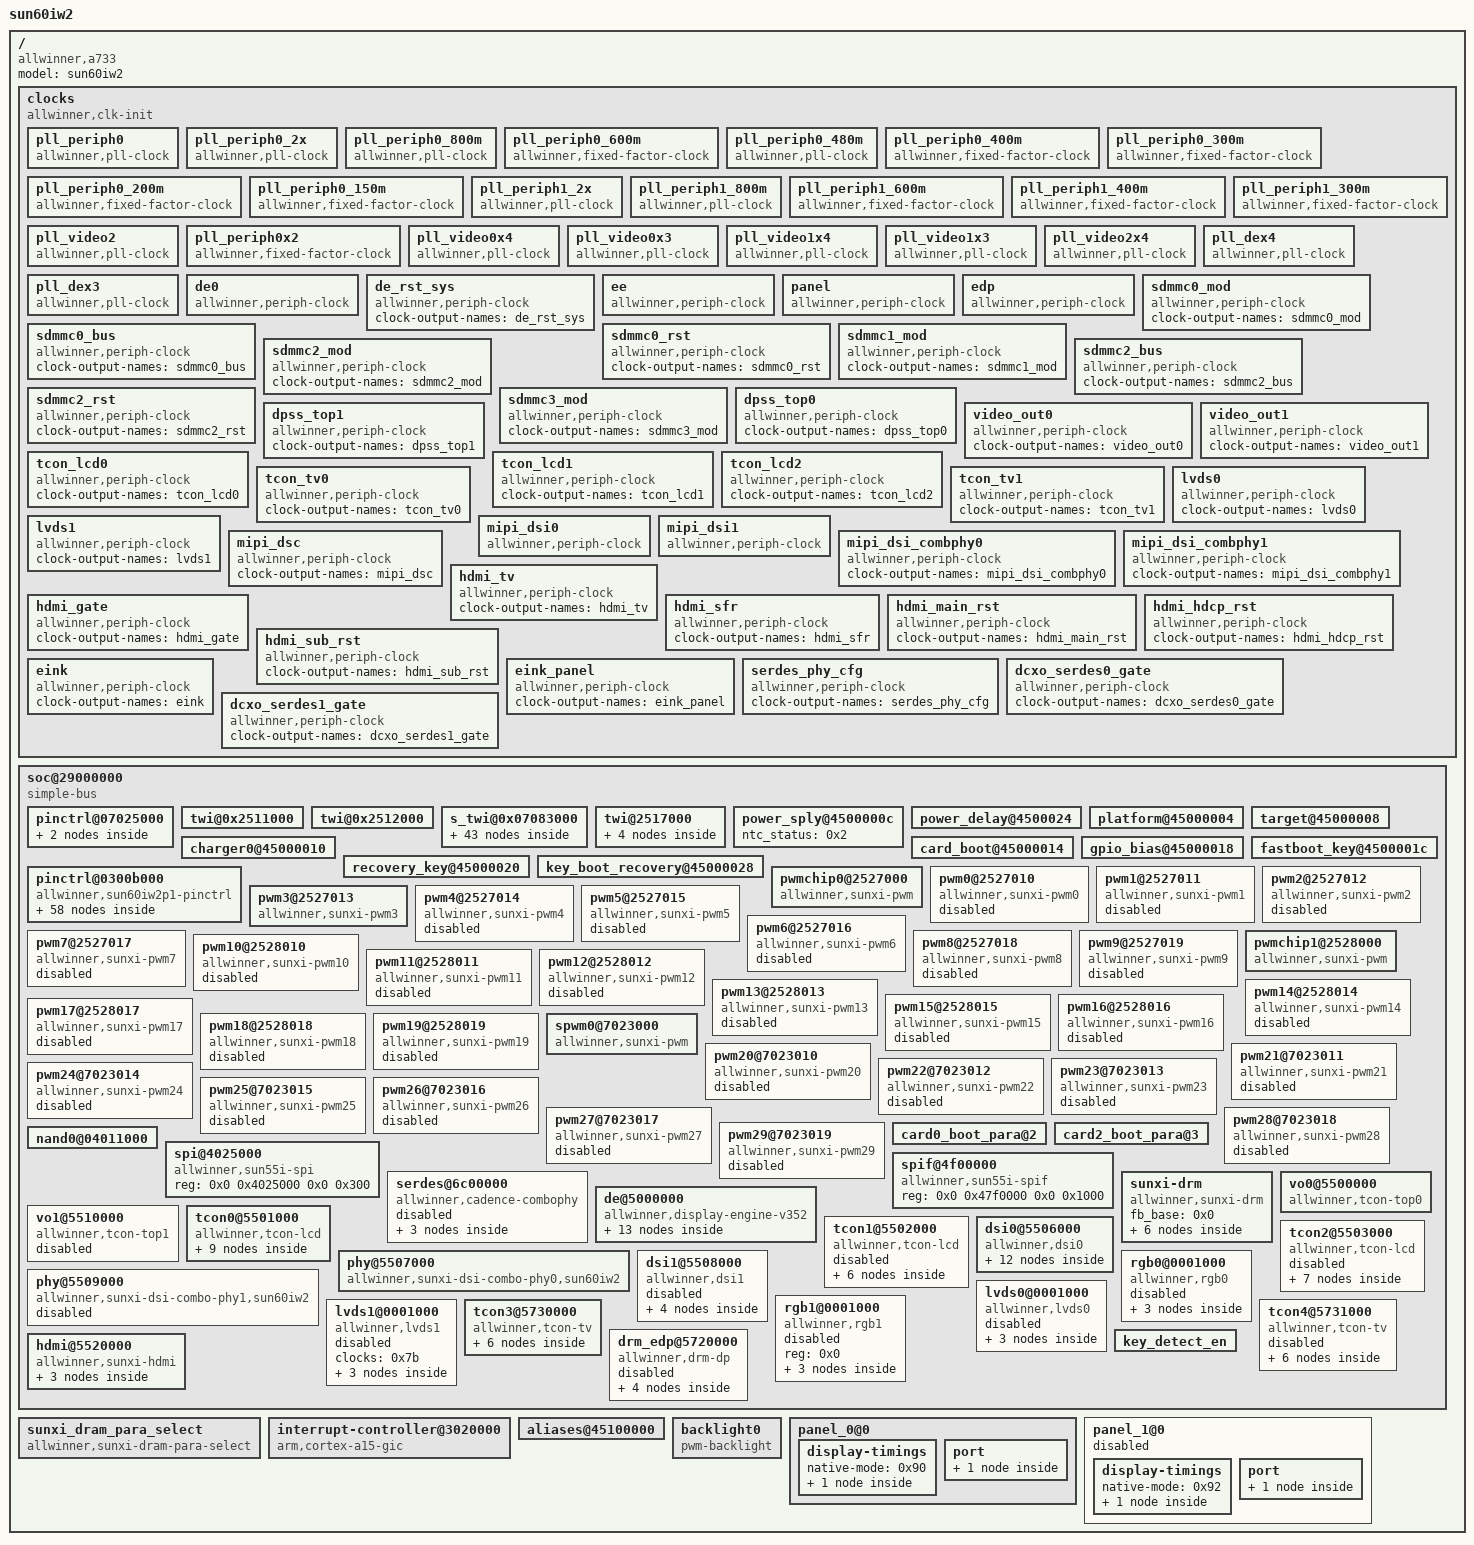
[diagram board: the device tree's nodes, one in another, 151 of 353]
/dts-v1/;

/ {
	model = "sun60iw2";
	compatible = "allwinner,a733", "arm,sun60iw2p1";
	#address-cells = <0x2>;
	#size-cells = <0x2>;

	clocks {
		compatible = "allwinner,clk-init";
		device_type = "clocks";
		#address-cells = <0x2>;
		#size-cells = <0x2>;
		ranges;
		reg = <0x0 0x2002000 0x0 0x2000 0x0 0x7010000 0x0 0x400>;

		pll_periph0 {
			#clock-cells = <0x0>;
			compatible = "allwinner,pll-clock";
			assigned-clock-rates = <0x23c34600>;
			lock-mode = "new";
			clock-output-names = "pll_periph0";
			phandle = <0x7>;
		};

		pll_periph0_2x {
			#clock-cells = <0x0>;
			compatible = "allwinner,pll-clock";
			lock-mode = "new";
			clock-output-names = "pll_periph0_2x";
			phandle = <0x1>;
		};

		pll_periph0_800m {
			#clock-cells = <0x0>;
			compatible = "allwinner,pll-clock";
			lock-mode = "new";
			clock-output-names = "pll_periph0_800m";
		};

		pll_periph0_600m {
			#clock-cells = <0x0>;
			compatible = "allwinner,fixed-factor-clock";
			clocks = <0x1>;
			clock-mult = <0x1>;
			clock-div = <0x2>;
			clock-output-names = "pll_periph0_600m";
			phandle = <0x2>;
		};

		pll_periph0_480m {
			#clock-cells = <0x0>;
			compatible = "allwinner,pll-clock";
			lock-mode = "new";
			clock-output-names = "pll_periph0_480m";
		};

		pll_periph0_400m {
			#clock-cells = <0x0>;
			compatible = "allwinner,fixed-factor-clock";
			clocks = <0x1>;
			clock-mult = <0x1>;
			clock-div = <0x3>;
			clock-output-names = "pll_periph0_400m";
			phandle = <0x3>;
		};

		pll_periph0_300m {
			#clock-cells = <0x0>;
			compatible = "allwinner,fixed-factor-clock";
			clocks = <0x2>;
			clock-mult = <0x1>;
			clock-div = <0x2>;
			clock-output-names = "pll_periph0_300m";
			phandle = <0x4>;
		};

		pll_periph0_200m {
			#clock-cells = <0x0>;
			compatible = "allwinner,fixed-factor-clock";
			clocks = <0x3>;
			clock-mult = <0x1>;
			clock-div = <0x2>;
			clock-output-names = "pll_periph0_200m";
		};

		pll_periph0_150m {
			#clock-cells = <0x0>;
			compatible = "allwinner,fixed-factor-clock";
			clocks = <0x4>;
			clock-mult = <0x1>;
			clock-div = <0x2>;
			clock-output-names = "pll_periph0_150m";
			phandle = <0x10>;
		};

		pll_periph1_2x {
			#clock-cells = <0x0>;
			compatible = "allwinner,pll-clock";
			lock-mode = "new";
			clock-output-names = "pll_periph1_2x";
			phandle = <0x5>;
		};

		pll_periph1_800m {
			#clock-cells = <0x0>;
			compatible = "allwinner,pll-clock";
			lock-mode = "new";
			clock-output-names = "pll_periph1_800m";
		};

		pll_periph1_600m {
			#clock-cells = <0x0>;
			compatible = "allwinner,fixed-factor-clock";
			clocks = <0x5>;
			clock-mult = <0x1>;
			clock-div = <0x2>;
			clock-output-names = "pll_periph1_600m";
			phandle = <0x6>;
		};

		pll_periph1_400m {
			#clock-cells = <0x0>;
			compatible = "allwinner,fixed-factor-clock";
			clocks = <0x5>;
			clock-mult = <0x1>;
			clock-div = <0x3>;
			clock-output-names = "pll_periph1_400m";
		};

		pll_periph1_300m {
			#clock-cells = <0x0>;
			compatible = "allwinner,fixed-factor-clock";
			clocks = <0x6>;
			clock-mult = <0x1>;
			clock-div = <0x2>;
			clock-output-names = "pll_periph1_300m";
		};

		pll_video2 {
			#clock-cells = <0x0>;
			compatible = "allwinner,pll-clock";
			lock-mode = "new";
			clock-output-names = "pll_video2";
			phandle = <0xc>;
		};

		pll_periph0x2 {
			#clock-cells = <0x0>;
			compatible = "allwinner,fixed-factor-clock";
			clocks = <0x7>;
			clock-mult = <0x2>;
			clock-div = <0x1>;
			clock-output-names = "pll_periph0x2";
			phandle = <0xa>;
		};

		pll_video0x4 {
			#clock-cells = <0x0>;
			compatible = "allwinner,pll-clock";
			lock-mode = "new";
			clock-output-names = "pll_video0x4";
		};

		pll_video0x3 {
			#clock-cells = <0x0>;
			compatible = "allwinner,pll-clock";
			lock-mode = "new";
			clock-output-names = "pll_video0x3";
		};

		pll_video1x4 {
			#clock-cells = <0x0>;
			compatible = "allwinner,pll-clock";
			lock-mode = "new";
			clock-output-names = "pll_video1x4";
			phandle = <0xf>;
		};

		pll_video1x3 {
			#clock-cells = <0x0>;
			compatible = "allwinner,pll-clock";
			lock-mode = "new";
			clock-output-names = "pll_video1x3";
		};

		pll_video2x4 {
			#clock-cells = <0x0>;
			compatible = "allwinner,pll-clock";
			lock-mode = "new";
			clock-output-names = "pll_video2x4";
		};

		pll_dex4 {
			#clock-cells = <0x0>;
			compatible = "allwinner,pll-clock";
			lock-mode = "new";
			clock-output-names = "pll_dex4";
		};

		pll_dex3 {
			#clock-cells = <0x0>;
			compatible = "allwinner,pll-clock";
			lock-mode = "new";
			clock-output-names = "pll_dex3";
			phandle = <0x8>;
		};

		de0 {
			#clock-cells = <0x0>;
			compatible = "allwinner,periph-clock";
			clock-output-names = "de0";
			assigned-clock-parents = <0x8>;
			assigned-clock-rates = <0x297c1e00>;
			assigned-clocks = <0x9>;
			phandle = <0x9>;
		};

		de_rst_sys {
			#clock-cells = <0x0>;
			compatible = "allwinner,periph-clock";
			clock-output-names = "de_rst_sys";
		};

		ee {
			#clock-cells = <0x0>;
			compatible = "allwinner,periph-clock";
			assigned-clock-parents = <0xa>;
			assigned-clock-rates = <0x11e1a300>;
			assigned-clocks = <0xb>;
			clock-output-names = "ee";
			phandle = <0xb>;
		};

		panel {
			#clock-cells = <0x0>;
			compatible = "allwinner,periph-clock";
			assigned-clock-parents = <0xc>;
			assigned-clock-rates = <0x1c9c380>;
			assigned-clocks = <0xd>;
			clock-output-names = "panel";
			phandle = <0xd>;
		};

		edp {
			#clock-cells = <0x0>;
			compatible = "allwinner,periph-clock";
			assigned-clocks = <0xe>;
			assigned-clock-parents = <0xf>;
			clock-output-names = "edp";
			phandle = <0xe>;
		};

		sdmmc0_mod {
			#clock-cells = <0x0>;
			compatible = "allwinner,periph-clock";
			clock-output-names = "sdmmc0_mod";
		};

		sdmmc0_bus {
			#clock-cells = <0x0>;
			compatible = "allwinner,periph-clock";
			clock-output-names = "sdmmc0_bus";
		};

		sdmmc0_rst {
			#clock-cells = <0x0>;
			compatible = "allwinner,periph-clock";
			clock-output-names = "sdmmc0_rst";
		};

		sdmmc1_mod {
			#clock-cells = <0x0>;
			compatible = "allwinner,periph-clock";
			clock-output-names = "sdmmc1_mod";
		};

		sdmmc2_mod {
			#clock-cells = <0x0>;
			compatible = "allwinner,periph-clock";
			clock-output-names = "sdmmc2_mod";
		};

		sdmmc2_bus {
			#clock-cells = <0x0>;
			compatible = "allwinner,periph-clock";
			clock-output-names = "sdmmc2_bus";
		};

		sdmmc2_rst {
			#clock-cells = <0x0>;
			compatible = "allwinner,periph-clock";
			clock-output-names = "sdmmc2_rst";
		};

		sdmmc3_mod {
			#clock-cells = <0x0>;
			compatible = "allwinner,periph-clock";
			clock-output-names = "sdmmc3_mod";
		};

		dpss_top0 {
			#clock-cells = <0x0>;
			compatible = "allwinner,periph-clock";
			clock-output-names = "dpss_top0";
			phandle = <0x5a>;
		};

		dpss_top1 {
			#clock-cells = <0x0>;
			compatible = "allwinner,periph-clock";
			clock-output-names = "dpss_top1";
			phandle = <0x5b>;
		};

		video_out0 {
			#clock-cells = <0x0>;
			compatible = "allwinner,periph-clock";
			clock-output-names = "video_out0";
		};

		video_out1 {
			#clock-cells = <0x0>;
			compatible = "allwinner,periph-clock";
			clock-output-names = "video_out1";
		};

		tcon_lcd0 {
			#clock-cells = <0x0>;
			compatible = "allwinner,periph-clock";
			clock-output-names = "tcon_lcd0";
			phandle = <0x5c>;
		};

		tcon_lcd1 {
			#clock-cells = <0x0>;
			compatible = "allwinner,periph-clock";
			clock-output-names = "tcon_lcd1";
			phandle = <0x63>;
		};

		tcon_lcd2 {
			#clock-cells = <0x0>;
			compatible = "allwinner,periph-clock";
			clock-output-names = "tcon_lcd2";
			phandle = <0x67>;
		};

		tcon_tv0 {
			#clock-cells = <0x0>;
			compatible = "allwinner,periph-clock";
			clock-output-names = "tcon_tv0";
			phandle = <0x7e>;
		};

		tcon_tv1 {
			#clock-cells = <0x0>;
			compatible = "allwinner,periph-clock";
			clock-output-names = "tcon_tv1";
			phandle = <0x82>;
		};

		lvds0 {
			#clock-cells = <0x0>;
			compatible = "allwinner,periph-clock";
			clock-output-names = "lvds0";
			phandle = <0x79>;
		};

		lvds1 {
			#clock-cells = <0x0>;
			compatible = "allwinner,periph-clock";
			clock-output-names = "lvds1";
			phandle = <0x7b>;
		};

		mipi_dsi0 {
			#clock-cells = <0x0>;
			compatible = "allwinner,periph-clock";
			assigned-clock-parents = <0x10>;
			assigned-clock-rates = <0x8f0d180>;
			clock-output-names = "mipi_dsi0";
			phandle = <0x6c>;
		};

		mipi_dsi1 {
			#clock-cells = <0x0>;
			compatible = "allwinner,periph-clock";
			assigned-clock-parents = <0x10>;
			assigned-clock-rates = <0x8f0d180>;
			clock-output-names = "mipi_dsi1";
			phandle = <0x75>;
		};

		mipi_dsc {
			#clock-cells = <0x0>;
			compatible = "allwinner,periph-clock";
			clock-output-names = "mipi_dsc";
			phandle = <0x6d>;
		};

		mipi_dsi_combphy0 {
			#clock-cells = <0x0>;
			compatible = "allwinner,periph-clock";
			clock-output-names = "mipi_dsi_combphy0";
		};

		mipi_dsi_combphy1 {
			#clock-cells = <0x0>;
			compatible = "allwinner,periph-clock";
			clock-output-names = "mipi_dsi_combphy1";
		};

		hdmi_tv {
			#clock-cells = <0x0>;
			compatible = "allwinner,periph-clock";
			clock-output-names = "hdmi_tv";
			phandle = <0x7d>;
		};

		hdmi_gate {
			#clock-cells = <0x0>;
			compatible = "allwinner,periph-clock";
			clock-output-names = "hdmi_gate";
			phandle = <0x87>;
		};

		hdmi_sfr {
			#clock-cells = <0x0>;
			compatible = "allwinner,periph-clock";
			clock-output-names = "hdmi_sfr";
			phandle = <0x88>;
		};

		hdmi_main_rst {
			#clock-cells = <0x0>;
			compatible = "allwinner,periph-clock";
			clock-output-names = "hdmi_main_rst";
			phandle = <0x89>;
		};

		hdmi_hdcp_rst {
			#clock-cells = <0x0>;
			compatible = "allwinner,periph-clock";
			clock-output-names = "hdmi_hdcp_rst";
		};

		hdmi_sub_rst {
			#clock-cells = <0x0>;
			compatible = "allwinner,periph-clock";
			clock-output-names = "hdmi_sub_rst";
			phandle = <0x8a>;
		};

		eink_panel {
			#clock-cells = <0x0>;
			compatible = "allwinner,periph-clock";
			clock-output-names = "eink_panel";
		};

		eink {
			#clock-cells = <0x0>;
			compatible = "allwinner,periph-clock";
			clock-output-names = "eink";
		};

		serdes_phy_cfg {
			#clock-cells = <0x0>;
			compatible = "allwinner,periph-clock";
			clock-output-names = "serdes_phy_cfg";
			phandle = <0x45>;
		};

		dcxo_serdes0_gate {
			#clock-cells = <0x0>;
			compatible = "allwinner,periph-clock";
			clock-output-names = "dcxo_serdes0_gate";
			phandle = <0x46>;
		};

		dcxo_serdes1_gate {
			#clock-cells = <0x0>;
			compatible = "allwinner,periph-clock";
			clock-output-names = "dcxo_serdes1_gate";
			phandle = <0x47>;
		};
	};

	soc@29000000 {
		compatible = "simple-bus";
		#address-cells = <0x2>;
		#size-cells = <0x2>;

		pinctrl@07025000 {

			s_twi0@0 {
				allwinner,pins = "PL0", "PL1";
				allwinner,pname = "s_twi0_scl", "s_twi0_sda";
				allwinner,function = "s_twi0";
				allwinner,muxsel = <0x2>;
				allwinner,drive = <0x1>;
				allwinner,pull = <0x1>;
				phandle = <0x17>;
			};

			s_twi0@1 {
				allwinner,pins = "PL0", "PL1";
				allwinner,function = "gpio_out";
				allwinner,muxsel = <0x1>;
				allwinner,drive = <0x1>;
				allwinner,pull = <0x1>;
				phandle = <0x18>;
			};
		};

		twi@0x2511000 {
			clock-frequency = <0x61a80>;
			pinctrl-0 = <0x11>;
			pinctrl-1 = <0x12>;
			twi-supply = <0x13>;
			status = "okay";
		};

		twi@0x2512000 {
			clock-frequency = <0x61a80>;
			pinctrl-0 = <0x14>;
			pinctrl-1 = <0x15>;
			twi-supply = <0x16>;
			status = "okay";
		};

		s_twi@0x07083000 {
			clock-frequency = <0x30d40>;
			pinctrl-0 = <0x17>;
			pinctrl-1 = <0x18>;
			twi-supply = <0x19>;
			status = "okay";

			pmu@34 {
			};

			pmu@36 {
				compatible = "x-powers,axp8191";
				reg = <0x36>;
				status = "okay";

				regulators@0 {

					dcdc1 {
						regulator-name = "axp8191-dcdc1";
						phandle = <0x1a>;
					};

					dcdc2 {
						regulator-name = "axp8191-dcdc2";
						phandle = <0x8b>;
					};

					dcdc3 {
						regulator-name = "axp8191-dcdc3";
					};

					dcdc4 {
						regulator-name = "axp8191-dcdc4";
					};

					dcdc5 {
						regulator-name = "axp8191-dcdc5";
					};

					dcdc6 {
						regulator-name = "axp8191-dcdc6";
					};

					dcdc7 {
						regulator-name = "axp8191-dcdc7";
					};

					dcdc8 {
						regulator-name = "axp8191-dcdc8";
					};

					dcdc9 {
						regulator-name = "axp8191-dcdc9";
					};

					rtcldo {
						regulator-name = "axp8191-rtcldo";
					};

					aldo1 {
						regulator-name = "axp8191-aldo1";
					};

					aldo2 {
						regulator-name = "axp8191-aldo2";
					};

					aldo3 {
						regulator-name = "axp8191-aldo3";
						phandle = <0x19>;
					};

					aldo4 {
						regulator-name = "axp8191-aldo4";
					};

					aldo5 {
						regulator-name = "axp8191-aldo5";
					};

					aldo6 {
						regulator-name = "axp8191-aldo6";
					};

					bldo1 {
						regulator-name = "axp8191-bldo1";
					};

					bldo2 {
						regulator-name = "axp8191-bldo2";
						phandle = <0x16>;
					};

					bldo3 {
						regulator-name = "axp8191-bldo3";
					};

					bldo4 {
						regulator-name = "axp8191-bldo4";
					};

					bldo5 {
						regulator-name = "axp8191-bldo5";
					};

					cldo1 {
						regulator-name = "axp8191-cldo1";
					};

					cldo2 {
						regulator-name = "axp8191-cldo2";
					};

					cldo3 {
						regulator-name = "axp8191-cldo3";
					};

					cldo4 {
						regulator-name = "axp8191-cldo4";
					};

					cldo5 {
						regulator-name = "axp8191-cldo5";
					};

					dldo1 {
						regulator-name = "axp8191-dldo1";
					};

					dldo2 {
						regulator-name = "axp8191-dldo2";
					};

					dldo3 {
						regulator-name = "axp8191-dldo3";
					};

					dldo4 {
						regulator-name = "axp8191-dldo4";
					};

					dldo5 {
						regulator-name = "axp8191-dldo5";
					};

					dldo6 {
						regulator-name = "axp8191-dldo6";
					};

					eldo1 {
						regulator-name = "axp8191-eldo1";
					};

					eldo2 {
						regulator-name = "axp8191-eldo2";
					};

					eldo3 {
						regulator-name = "axp8191-eldo3";
					};

					eldo4 {
						regulator-name = "axp8191-eldo4";
					};

					eldo5 {
						regulator-name = "axp8191-eldo5";
					};

					eldo6 {
						regulator-name = "axp8191-eldo6";
					};

					dc1sw1 {
						regulator-name = "axp8191-dc1sw1";
						swin-supply = <0x1a>;
						phandle = <0x8e>;
					};

					dc1sw2 {
						regulator-name = "axp8191-dc1sw2";
						swin-supply = <0x1a>;
						phandle = <0x13>;
					};
				};
			};
		};

		twi@2517000 {
			clock-frequency = <0x61a80>;
			pinctrl-0 = <0x1b>;
			pinctrl-1 = <0x1c>;
			twi-supply = <0x16>;
			status = "okay";

			ocp2131@3e {
				compatible = "general,ocp2131";
				reg = <0x3e>;
				status = "okay";

				regulators@1 {

					ocp2131-avdd {
						regulator-name = "ocp2131-avdd";
					};

					ocp2131-avee {
						regulator-name = "ocp2131-avee";
					};
				};
			};
		};

		power_sply@4500000c {
			device_type = "power_sply";
			ntc_status = <0x2>;
		};

		power_delay@4500024 {
			device_type = "power_delay";
		};

		platform@45000004 {
			device_type = "platform";
			eraseflag = <0x1>;
			next_work = <0x3>;
			debug_mode = <0x4>;
		};

		target@45000008 {
			device_type = "target";
			boot_clock = <0x3f0>;
			storage_type = <0xffffffff>;
			burn_key = <0x1>;
			dragonboard_test = <0x0>;
			auto_fel = <0x1>;
		};

		charger0@45000010 {
			device_type = "charger0";
			pmu_safe_vol = <0xd48>;
			bat_bmp_type = <0x1>;
			ntc_cur = <0x3c>;
			safe_temp_H = <0x258>;
			safe_temp_L = <0xffffff06>;
			pmu_bat_temp_para1 = <0x154a>;
			pmu_bat_temp_para2 = <0xcf3>;
			pmu_bat_temp_para3 = <0xa38>;
			pmu_bat_temp_para4 = <0x81f>;
			pmu_bat_temp_para5 = <0x680>;
			pmu_bat_temp_para6 = <0x53c>;
			pmu_bat_temp_para7 = <0x43e>;
			pmu_bat_temp_para8 = <0x2d7>;
			pmu_bat_temp_para9 = <0x1f2>;
			pmu_bat_temp_para10 = <0x15c>;
			pmu_bat_temp_para11 = <0x125>;
			pmu_bat_temp_para12 = <0xf8>;
			pmu_bat_temp_para13 = <0xd3>;
			pmu_bat_temp_para14 = <0xb4>;
			pmu_bat_temp_para15 = <0x85>;
			pmu_bat_temp_para16 = <0x64>;
		};

		card_boot@45000014 {
			device_type = "card_boot";
			logical_start = <0xa000>;
			sprite_gpio0 = <0x1d 0x7 0x6 0x1 0xffffffff 0xffffffff 0x1>;
		};

		gpio_bias@45000018 {
			device_type = "gpio_bias";
		};

		fastboot_key@4500001c {
			device_type = "fastboot_key";
			key_max = <0x2a>;
			key_min = <0x26>;
		};

		recovery_key@45000020 {
			device_type = "recovery_key";
			key_max = <0x1f>;
			key_min = <0x1c>;
		};

		key_boot_recovery@45000028 {
			device_type = "key_boot_recovery";
			recovery_key_used = <0x1>;
			press_mode_enable = <0x0>;
			key_work_mode = <0x2>;
			short_press_mode = <0x0>;
			long_press_mode = <0x1>;
			key_press_time = <0x7d0>;
			recovery_key = <0x1d 0xb 0x8 0x0 0x1 0x3 0x1>;
		};

		pinctrl@0300b000 {
			compatible = "allwinner,sun60iw2p1-pinctrl";
			device_type = "pio";
			gpio-controller;
			#size-cells = <0x0>;
			#gpio-cells = <0x6>;
			input-debounce = <0x0 0x0 0x0 0x0 0x0 0x0 0x0 0x0 0x0>;
			phandle = <0x1d>;

			sdc0@0 {
				allwinner,pins = "PF0", "PF1", "PF3", "PF4", "PF5";
				allwinner,function = "sdc0";
				allwinner,muxsel = <0x2>;
				allwinner,drive = <0x0>;
				allwinner,pull = <0x1>;
				phandle = <0x40>;
			};

			sdc0@1 {
				allwinner,pins = "PF2";
				allwinner,function = "sdc0";
				allwinner,muxsel = <0x2>;
				allwinner,drive = <0x2>;
				allwinner,pull = <0x1>;
				phandle = <0x41>;
			};

			sdc0@2 {
				allwinner,pins = "PF0", "PF1", "PF2", "PF3", "PF4", "PF5";
				allwinner,function = "uart0_jtag";
				allwinner,muxsel = <0x3>;
				allwinner,drive = <0x0>;
				allwinner,pull = <0x1>;
			};

			sdc2@0 {
				allwinner,pins = "PC6", "PC8", "PC9", "PC10", "PC11", "PC13", "PC14", "PC15", "PC16";
				allwinner,function = "sdc2";
				allwinner,muxsel = <0x3>;
				allwinner,drive = <0x1>;
				allwinner,pull = <0x1>;
				phandle = <0x42>;
			};

			sdc2@1 {
				allwinner,pins = "PC1", "PC5";
				allwinner,function = "sdc2";
				allwinner,muxsel = <0x3>;
				allwinner,drive = <0x3>;
				allwinner,pull = <0x1>;
				phandle = <0x44>;
			};

			sdc2@2 {
				allwinner,pins = "PC0";
				allwinner,function = "sdc2";
				allwinner,muxsel = <0x3>;
				allwinner,drive = <0x3>;
				allwinner,pull = <0x2>;
				phandle = <0x43>;
			};

			nand0@0 {
			};

			nand0@1 {
			};

			nand0@2 {
			};

			spi0@0 {
			};

			spi0@1 {
			};

			spi0@2 {
			};

			spif@0 {
			};

			spif@1 {
			};

			spif@2 {
			};

			lvds0@0 {
			};

			lvds0@1 {
			};

			lvds1@0 {
			};

			lvds1@1 {
			};

			lvds2@0 {
			};

			lvds2@1 {
			};

			lvds3@0 {
			};

			lvds3@1 {
			};

			lcd1_lvds2link@0 {
			};

			lcd1_lvds2link@1 {
			};

			lvds2link@0 {
			};

			lvds2link@1 {
			};

			rgb24@0 {
			};

			rgb24@1 {
			};

			rgb18@0 {
			};

			rgb18@1 {
			};

			eink@0 {
			};

			eink@1 {
			};

			dsi4lane@0 {
			};

			dsi4lane@1 {
			};

			dsi0_4lane@0 {
				phandle = <0x6f>;
			};

			dsi0_4lane@1 {
				phandle = <0x70>;
			};

			dsi1_4lane@0 {
			};

			dsi1_4lane@1 {
			};

			pwm0@0 {
			};

			pwm0@1 {
			};

			pwm1@0 {
			};

			pwm1@1 {
			};

			pwm2@0 {
			};

			pwm2@1 {
			};

			pwm3@0 {
				allwinner,pins = "PD21";
				allwinner,function = "pwm0_3";
				allwinner,muxsel = <0x9>;
				allwinner,drive = <0x3>;
				allwinner,pull = <0x2>;
				phandle = <0x28>;
			};

			pwm3@1 {
				allwinner,pins = "PD21";
				allwinner,function = "io_disabled";
				allwinner,muxsel = <0xf>;
				allwinner,drive = <0x3>;
				allwinner,pull = <0x2>;
				phandle = <0x29>;
			};

			pwm4@0 {
				allwinner,pins = "PD22";
				allwinner,function = "pwm0_4";
				allwinner,muxsel = <0x2>;
				allwinner,drive = <0x3>;
				allwinner,pull = <0x2>;
				phandle = <0x2a>;
			};

			pwm4@1 {
				allwinner,pins = "PD22";
				allwinner,function = "io_disabled";
				allwinner,muxsel = <0xf>;
				allwinner,drive = <0x3>;
				allwinner,pull = <0x2>;
				phandle = <0x2b>;
			};

			pwm19@0 {
			};

			pwm19@1 {
			};

			twi1@0 {
				allwinner,pins = "PH2", "PH3";
				allwinner,pname = "twi1_scl", "twi1_sda";
				allwinner,function = "twi1";
				allwinner,muxsel = <0x2>;
				allwinner,drive = <0x1>;
				allwinner,pull = <0x1>;
				phandle = <0x11>;
			};

			twi1@1 {
				allwinner,pins = "PH2", "PH3";
				allwinner,function = "gpio_out";
				allwinner,muxsel = <0x1>;
				allwinner,drive = <0x1>;
				allwinner,pull = <0x1>;
				phandle = <0x12>;
			};

			dram_para_select_pin@0 {
				allwinner,pins = "PH16";
				allwinner,function = "gpio_in";
				allwinner,muxsel = <0x0>;
				allwinner,drive = <0x0>;
				allwinner,pull = <0x1>;
				phandle = <0x8c>;
			};

			twi2@0 {
				allwinner,pins = "PD22", "PD23";
				allwinner,pname = "twi0_scl", "twi0_sda";
				allwinner,function = "twi0";
				allwinner,muxsel = <0x7>;
				allwinner,drive = <0x1>;
				allwinner,pull = <0x1>;
				phandle = <0x14>;
			};

			twi2@1 {
				allwinner,pins = "PD22", "PD23";
				allwinner,function = "gpio_out";
				allwinner,muxsel = <0x1>;
				allwinner,drive = <0x1>;
				allwinner,pull = <0x1>;
				phandle = <0x15>;
			};

			twi7@0 {
				allwinner,pins = "PJ22", "PJ23";
				allwinner,pname = "twi7_scl", "twi7_sda";
				allwinner,function = "twi7";
				allwinner,muxsel = <0x6>;
				allwinner,drive = <0x1>;
				allwinner,pull = <0x1>;
				phandle = <0x1b>;
			};

			twi7@1 {
				allwinner,pins = "PJ22", "PJ23";
				allwinner,function = "gpio_out";
				allwinner,muxsel = <0x1>;
				allwinner,drive = <0x1>;
				allwinner,pull = <0x1>;
				phandle = <0x1c>;
			};
		};

		pwmchip0@2527000 {
			#pwm-cells = <0x3>;
			compatible = "allwinner,sunxi-pwm";
			reg = <0x0 0x2527000 0x0 0x400>;
			pwm-number = <0xa>;
			pwm-base = <0x0>;
			sunxi-pwms = <0x1e 0x1f 0x20 0x21 0x22 0x23 0x24 0x25 0x26 0x27>;
		};

		pwm0@2527010 {
			#pwm-cells = <0x3>;
			compatible = "allwinner,sunxi-pwm0";
			reg = <0x0 0x2527010 0x0 0x4>;
			reg_base = <0x2527000>;
			status = "disabled";
			phandle = <0x1e>;
		};

		pwm1@2527011 {
			#pwm-cells = <0x3>;
			compatible = "allwinner,sunxi-pwm1";
			reg = <0x0 0x2527011 0x0 0x4>;
			reg_base = <0x2527000>;
			status = "disabled";
			phandle = <0x1f>;
		};

		pwm2@2527012 {
			#pwm-cells = <0x3>;
			compatible = "allwinner,sunxi-pwm2";
			reg = <0x0 0x2527012 0x0 0x4>;
			reg_base = <0x2527000>;
			status = "disabled";
			phandle = <0x20>;
		};

		pwm3@2527013 {
			#pwm-cells = <0x3>;
			compatible = "allwinner,sunxi-pwm3";
			reg = <0x0 0x2527013 0x0 0x4>;
			reg_base = <0x2527000>;
			status = "okay";
			pinctrl-names = "active", "sleep";
			pinctrl-0 = <0x28>;
			pinctrl-1 = <0x29>;
			phandle = <0x21>;
		};

		pwm4@2527014 {
			#pwm-cells = <0x3>;
			compatible = "allwinner,sunxi-pwm4";
			reg = <0x0 0x2527014 0x0 0x4>;
			reg_base = <0x2527000>;
			status = "disabled";
			pinctrl-names = "active", "sleep";
			pinctrl-0 = <0x2a>;
			pinctrl-1 = <0x2b>;
			phandle = <0x22>;
		};

		pwm5@2527015 {
			#pwm-cells = <0x3>;
			compatible = "allwinner,sunxi-pwm5";
			reg = <0x0 0x2527015 0x0 0x4>;
			reg_base = <0x2527000>;
			status = "disabled";
			phandle = <0x23>;
		};

		pwm6@2527016 {
			#pwm-cells = <0x3>;
			compatible = "allwinner,sunxi-pwm6";
			reg = <0x0 0x2527016 0x0 0x4>;
			reg_base = <0x2527000>;
			status = "disabled";
			phandle = <0x24>;
		};

		pwm7@2527017 {
			#pwm-cells = <0x3>;
			compatible = "allwinner,sunxi-pwm7";
			reg = <0x0 0x2527017 0x0 0x4>;
			reg_base = <0x2527000>;
			status = "disabled";
			phandle = <0x25>;
		};

		pwm8@2527018 {
			#pwm-cells = <0x3>;
			compatible = "allwinner,sunxi-pwm8";
			reg = <0x0 0x2527018 0x0 0x4>;
			reg_base = <0x2527000>;
			status = "disabled";
			phandle = <0x26>;
		};

		pwm9@2527019 {
			#pwm-cells = <0x3>;
			compatible = "allwinner,sunxi-pwm9";
			reg = <0x0 0x2527019 0x0 0x4>;
			reg_base = <0x2527000>;
			status = "disabled";
			phandle = <0x27>;
		};

		pwmchip1@2528000 {
			#pwm-cells = <0x3>;
			compatible = "allwinner,sunxi-pwm";
			reg = <0x0 0x2528000 0x0 0x400>;
			pwm-number = <0xa>;
			pwm-base = <0xa>;
			sunxi-pwms = <0x2c 0x2d 0x2e 0x2f 0x30 0x31 0x32 0x33 0x34 0x35>;
		};

		pwm10@2528010 {
			#pwm-cells = <0x3>;
			compatible = "allwinner,sunxi-pwm10";
			reg = <0x0 0x2528010 0x0 0x4>;
			reg_base = <0x2528000>;
			status = "disabled";
			phandle = <0x2c>;
		};

		pwm11@2528011 {
			#pwm-cells = <0x3>;
			compatible = "allwinner,sunxi-pwm11";
			reg = <0x0 0x2528011 0x0 0x4>;
			reg_base = <0x2528000>;
			status = "disabled";
			phandle = <0x2d>;
		};

		pwm12@2528012 {
			#pwm-cells = <0x3>;
			compatible = "allwinner,sunxi-pwm12";
			reg = <0x0 0x2528012 0x0 0x4>;
			reg_base = <0x2528000>;
			status = "disabled";
			phandle = <0x2e>;
		};

		pwm13@2528013 {
			#pwm-cells = <0x3>;
			compatible = "allwinner,sunxi-pwm13";
			reg = <0x0 0x2528013 0x0 0x4>;
			reg_base = <0x2528000>;
			status = "disabled";
			phandle = <0x2f>;
		};

		pwm14@2528014 {
			#pwm-cells = <0x3>;
			compatible = "allwinner,sunxi-pwm14";
			reg = <0x0 0x2528014 0x0 0x4>;
			reg_base = <0x2528000>;
			status = "disabled";
			phandle = <0x30>;
		};

		pwm15@2528015 {
			#pwm-cells = <0x3>;
			compatible = "allwinner,sunxi-pwm15";
			reg = <0x0 0x2528015 0x0 0x4>;
			reg_base = <0x2528000>;
			status = "disabled";
			phandle = <0x31>;
		};

		pwm16@2528016 {
			#pwm-cells = <0x3>;
			compatible = "allwinner,sunxi-pwm16";
			reg = <0x0 0x2528016 0x0 0x4>;
			reg_base = <0x2528000>;
			status = "disabled";
			phandle = <0x32>;
		};

		pwm17@2528017 {
			#pwm-cells = <0x3>;
			compatible = "allwinner,sunxi-pwm17";
			reg = <0x0 0x2528017 0x0 0x4>;
			reg_base = <0x2528000>;
			status = "disabled";
			phandle = <0x33>;
		};

		pwm18@2528018 {
			#pwm-cells = <0x3>;
			compatible = "allwinner,sunxi-pwm18";
			reg = <0x0 0x2528018 0x0 0x4>;
			reg_base = <0x2528000>;
			status = "disabled";
			phandle = <0x34>;
		};

		pwm19@2528019 {
			#pwm-cells = <0x3>;
			compatible = "allwinner,sunxi-pwm19";
			reg = <0x0 0x2528019 0x0 0x4>;
			reg_base = <0x2528000>;
			status = "disabled";
			phandle = <0x35>;
		};

		spwm0@7023000 {
			#pwm-cells = <0x3>;
			compatible = "allwinner,sunxi-pwm";
			reg = <0x0 0x7023000 0x0 0x400>;
			pwm-number = <0xa>;
			pwm-base = <0x14>;
			sunxi-pwms = <0x36 0x37 0x38 0x39 0x3a 0x3b 0x3c 0x3d 0x3e 0x3f>;
		};

		pwm20@7023010 {
			#pwm-cells = <0x3>;
			compatible = "allwinner,sunxi-pwm20";
			reg = <0x0 0x7023010 0x0 0x4>;
			reg_base = <0x7023000>;
			status = "disabled";
			phandle = <0x36>;
		};

		pwm21@7023011 {
			#pwm-cells = <0x3>;
			compatible = "allwinner,sunxi-pwm21";
			reg = <0x0 0x7023011 0x0 0x4>;
			reg_base = <0x7023000>;
			status = "disabled";
			phandle = <0x37>;
		};

		pwm22@7023012 {
			#pwm-cells = <0x3>;
			compatible = "allwinner,sunxi-pwm22";
			reg = <0x0 0x7023012 0x0 0x4>;
			reg_base = <0x7023000>;
			status = "disabled";
			phandle = <0x38>;
		};

		pwm23@7023013 {
			#pwm-cells = <0x3>;
			compatible = "allwinner,sunxi-pwm23";
			reg = <0x0 0x7023013 0x0 0x4>;
			reg_base = <0x7023000>;
			status = "disabled";
			phandle = <0x39>;
		};

		pwm24@7023014 {
			#pwm-cells = <0x3>;
			compatible = "allwinner,sunxi-pwm24";
			reg = <0x0 0x7023014 0x0 0x4>;
			reg_base = <0x7023000>;
			status = "disabled";
			phandle = <0x3a>;
		};

		pwm25@7023015 {
			#pwm-cells = <0x3>;
			compatible = "allwinner,sunxi-pwm25";
			reg = <0x0 0x7023015 0x0 0x4>;
			reg_base = <0x7023000>;
			status = "disabled";
			phandle = <0x3b>;
		};

		pwm26@7023016 {
			#pwm-cells = <0x3>;
			compatible = "allwinner,sunxi-pwm26";
			reg = <0x0 0x7023016 0x0 0x4>;
			reg_base = <0x7023000>;
			status = "disabled";
			phandle = <0x3c>;
		};

		pwm27@7023017 {
			#pwm-cells = <0x3>;
			compatible = "allwinner,sunxi-pwm27";
			reg = <0x0 0x7023017 0x0 0x4>;
			reg_base = <0x7023000>;
			status = "disabled";
			phandle = <0x3d>;
		};

		pwm28@7023018 {
			#pwm-cells = <0x3>;
			compatible = "allwinner,sunxi-pwm28";
			reg = <0x0 0x7023018 0x0 0x4>;
			reg_base = <0x7023000>;
			status = "disabled";
			phandle = <0x3e>;
		};

		pwm29@7023019 {
			#pwm-cells = <0x3>;
			compatible = "allwinner,sunxi-pwm29";
			reg = <0x0 0x7023019 0x0 0x4>;
			reg_base = <0x7023000>;
			status = "disabled";
			phandle = <0x3f>;
		};

		card0_boot_para@2 {
			device_type = "card0_boot_para";
			card_ctrl = <0x0>;
			card_high_speed = <0x1>;
			card_line = <0x4>;
			clk_mmc = "sdmmc0_mod";
			pll-0 = "hosc";
			pll-1 = "pll_periph1_400m";
			pll-2 = "pll_periph1_300m";
			pinctrl-0 = <0x40 0x41>;
			clk_type = "typ1";
		};

		card2_boot_para@3 {
			device_type = "card2_boot_para";
			reg = <0x0 0x3 0x0 0x0>;
			card_ctrl = <0x2>;
			card_high_speed = <0x1>;
			card_line = <0x8>;
			clk_mmc = "sdmmc2_mod";
			pll-0 = "hosc";
			pll-1 = "pll_periph1_800m";
			pll-2 = "pll_periph1_600m";
			pinctrl-0 = <0x42 0x43 0x44>;
			sdc_ex_dly_used = <0x2>;
			sdc_tm4_hs200_max_freq = <0xc8>;
			sdc_tm4_hs400_max_freq = <0xc8>;
			sdc_tm4_win_th = <0x7>;
			sdc_io_1v8 = <0x1>;
			sdc_type = "tm4";
			clk_type = "typ1";
			status = "okay";
		};

		nand0@04011000 {
			device_type = "nand0";
		};

		spi@4025000 {
			#address-cells = <0x1>;
			#size-cells = <0x0>;
			compatible = "allwinner,sun55i-spi";
			device_type = "spi0";
			reg = <0x0 0x4025000 0x0 0x300>;
		};

		spif@4f00000 {
			#address-cells = <0x1>;
			#size-cells = <0x0>;
			compatible = "allwinner,sun55i-spif";
			device_type = "spif";
			reg = <0x0 0x47f0000 0x0 0x1000>;
		};

		serdes@6c00000 {
			compatible = "allwinner,cadence-combophy";
			reg = <0x0 0x6c00000 0x0 0x400 0x0 0x6c06000 0x0 0x2000 0x0 0x709016c 0x0 0x4>;
			clocks = <0x45 0x46 0x47>;
			clock-names = "serdes-clk", "dcxo-serdes0-clk", "dcxo-serdes1-clk";
			#address-cells = <0x2>;
			#size-cells = <0x2>;
			ranges;
			status = "disabled";

			combo-phy0@6c01000 {
				reg = <0x0 0x6c01000 0x0 0xa00 0x0 0x6c80000 0x0 0x20000>;
				#phy-cells = <0x1>;
				phandle = <0x86>;
			};

			combo-phy1@6c02000 {
				reg = <0x0 0x6c02000 0x0 0xa00 0x0 0x6ca0000 0x0 0x20000>;
				#phy-cells = <0x1>;
			};

			aux-hpd@6c01e00 {
				reg = <0x0 0x6c01e00 0x0 0x200>;
				#phy-cells = <0x1>;
				phandle = <0x85>;
			};
		};

		sunxi-drm {
			compatible = "allwinner,sunxi-drm";
			fb_base = <0x0>;
			status = "okay";

			route {

				route_edp {
					status = "disabled";
					endpoints = <0x48 0x49>;
					logo,uboot = "bootlogo.bmp";
				};

				route_lvds0 {
					status = "disabled";
					endpoints = <0x4a 0x4b>;
					logo,uboot = "bootlogo.bmp";
				};

				route_rgb0 {
					status = "disabled";
					endpoints = <0x4a 0x4c>;
					logo,uboot = "bootlogo.bmp";
				};

				route_dsi0 {
					status = "okay";
					endpoints = <0x4a 0x4d>;
					logo,uboot = "bootlogo.bmp";
				};

				route_hdmi {
					status = "okay";
					endpoints = <0x4e 0x4f>;
					logo,uboot = "bootlogo.bmp";
				};
			};
		};

		de@5000000 {
			compatible = "allwinner,display-engine-v352";
			reg = <0x0 0x5000000 0x0 0x400000>;
			interrupts = <0x0 0x32 0x4 0x0 0x22 0x4>;
			clocks = <0x9>;
			clock-names = "clk_de";
			status = "okay";
			chn_cfg_mode = <0x2>;

			ports {
				#address-cells = <0x1>;
				#size-cells = <0x0>;

				port@0 {
					reg = <0x0>;
					#address-cells = <0x1>;
					#size-cells = <0x0>;

					endpoint@0 {
						reg = <0x0>;
						remote-endpoint = <0x50>;
						phandle = <0x4a>;
					};

					endpoint@1 {
						reg = <0x1>;
						remote-endpoint = <0x51>;
						phandle = <0x64>;
					};

					endpoint@2 {
						reg = <0x2>;
						remote-endpoint = <0x52>;
						phandle = <0x68>;
					};

					endpoint@3 {
						reg = <0x4>;
						remote-endpoint = <0x53>;
						phandle = <0x80>;
					};

					endpoint@4 {
						reg = <0x5>;
						remote-endpoint = <0x54>;
						phandle = <0x48>;
					};
				};

				port@1 {
					reg = <0x1>;
					#address-cells = <0x1>;
					#size-cells = <0x0>;

					endpoint@0 {
						reg = <0x0>;
						remote-endpoint = <0x55>;
						phandle = <0x5e>;
					};

					endpoint@1 {
						reg = <0x1>;
						remote-endpoint = <0x56>;
						phandle = <0x65>;
					};

					endpoint@2 {
						reg = <0x2>;
						remote-endpoint = <0x57>;
						phandle = <0x69>;
					};

					endpoint@3 {
						reg = <0x4>;
						remote-endpoint = <0x58>;
						phandle = <0x4e>;
					};

					endpoint@4 {
						reg = <0x5>;
						remote-endpoint = <0x59>;
						phandle = <0x83>;
					};
				};
			};
		};

		vo0@5500000 {
			compatible = "allwinner,tcon-top0";
			reg = <0x0 0x5500000 0x0 0x1000>;
			clocks = <0x5a>;
			clock-names = "clk_bus_dpss_top";
			status = "okay";
			phandle = <0x5d>;
		};

		vo1@5510000 {
			compatible = "allwinner,tcon-top1";
			reg = <0x0 0x5510000 0x0 0x1000>;
			clocks = <0x5b>;
			clock-names = "clk_bus_dpss_top";
			status = "disabled";
			phandle = <0x7f>;
		};

		tcon0@5501000 {
			compatible = "allwinner,tcon-lcd";
			reg = <0x0 0x5501000 0x0 0x1000>;
			interrupts = <0x0 0x36 0x4>;
			clocks = <0x5c>;
			clock-names = "clk_tcon";
			top = <0x5d>;
			status = "okay";

			ports {
				#address-cells = <0x1>;
				#size-cells = <0x0>;

				port@0 {
					#address-cells = <0x1>;
					#size-cells = <0x0>;
					reg = <0x0>;

					endpoint@0 {
						reg = <0x0>;
						remote-endpoint = <0x4a>;
						phandle = <0x50>;
					};

					endpoint@1 {
						reg = <0x1>;
						remote-endpoint = <0x5e>;
						phandle = <0x55>;
					};
				};

				port@1 {
					#address-cells = <0x1>;
					#size-cells = <0x0>;
					reg = <0x1>;

					endpoint@0 {
						reg = <0x0>;
						remote-endpoint = <0x5f>;
						phandle = <0x4d>;
					};

					endpoint@1 {
						reg = <0x1>;
						remote-endpoint = <0x60>;
						phandle = <0x78>;
					};

					endpoint@2 {
						reg = <0x2>;
						remote-endpoint = <0x61>;
						phandle = <0x4b>;
					};

					endpoint@3 {
						reg = <0x3>;
						remote-endpoint = <0x62>;
						phandle = <0x4c>;
					};
				};
			};
		};

		tcon1@5502000 {
			compatible = "allwinner,tcon-lcd";
			reg = <0x0 0x5502000 0x0 0x1000>;
			interrupts = <0x0 0x37 0x4>;
			clocks = <0x63>;
			clock-names = "clk_tcon";
			top = <0x5d>;
			status = "disabled";

			ports {
				#address-cells = <0x1>;
				#size-cells = <0x0>;

				port@0 {
					reg = <0x0>;
					#address-cells = <0x1>;
					#size-cells = <0x0>;

					endpoint@0 {
						reg = <0x0>;
						remote-endpoint = <0x64>;
						phandle = <0x51>;
					};

					endpoint@1 {
						reg = <0x1>;
						remote-endpoint = <0x65>;
						phandle = <0x56>;
					};
				};

				port@1 {
					#address-cells = <0x1>;
					#size-cells = <0x0>;
					reg = <0x1>;

					endpoint@0 {
						reg = <0x0>;
						remote-endpoint = <0x66>;
						phandle = <0x77>;
					};
				};
			};
		};

		tcon2@5503000 {
			compatible = "allwinner,tcon-lcd";
			reg = <0x0 0x5503000 0x0 0x1000>;
			interrupts = <0x0 0x38 0x4>;
			clocks = <0x67>;
			clock-names = "clk_tcon";
			top = <0x5d>;
			status = "disabled";

			ports {
				#address-cells = <0x1>;
				#size-cells = <0x0>;

				port@0 {
					#address-cells = <0x1>;
					#size-cells = <0x0>;
					reg = <0x0>;

					endpoint@0 {
						reg = <0x0>;
						remote-endpoint = <0x68>;
						phandle = <0x52>;
					};

					endpoint@1 {
						reg = <0x1>;
						remote-endpoint = <0x69>;
						phandle = <0x57>;
					};
				};

				port@1 {
					#address-cells = <0x1>;
					#size-cells = <0x0>;
					reg = <0x1>;

					endpoint@0 {
						reg = <0x0>;
						remote-endpoint = <0x6a>;
						phandle = <0x7c>;
					};

					endpoint@1 {
						reg = <0x1>;
						remote-endpoint = <0x6b>;
						phandle = <0x7a>;
					};
				};
			};
		};

		phy@5507000 {
			compatible = "allwinner,sunxi-dsi-combo-phy0,sun60iw2";
			reg = <0x0 0x5507000 0x0 0x1ff>;
			clocks = <0x6c>;
			clock-names = "phy_clk";
			#phy-cells = <0x0>;
			status = "okay";
			phandle = <0x6e>;
		};

		dsi0@5506000 {
			compatible = "allwinner,dsi0";
			reg = <0x0 0x5506000 0x0 0xfff 0x0 0x5504000 0x0 0xfff>;
			interrupts = <0x0 0x3b 0x4>;
			clocks = <0x6c 0x6d>;
			clock-names = "dsi_clk", "dsc_clk";
			phys = <0x6e>;
			phy-names = "combophy";
			status = "okay";
			pinctrl-0 = <0x6f>;
			pinctrl-1 = <0x70>;
			pinctrl-names = "active", "sleep";

			ports {
				#address-cells = <0x1>;
				#size-cells = <0x0>;

				port@0 {
					#address-cells = <0x1>;
					#size-cells = <0x0>;
					reg = <0x0>;

					endpoint@0 {
						reg = <0x0>;
						remote-endpoint = <0x4d>;
						phandle = <0x5f>;
					};
				};

				port@1 {

					endpoint {
						remote-endpoint = <0x71>;
						phandle = <0x72>;
					};
				};
			};

			panel@0 {
				compatible = "allwinner,virtual-panel";
				status = "okay";
				reg = <0x0>;

				ports {

					port@0 {
						reg = <0x0>;

						endpoint@0 {
							reg = <0x0>;
							remote-endpoint = <0x72>;
							phandle = <0x71>;
						};
					};

					port@1 {
						reg = <0x1>;

						endpoint@0 {
							reg = <0x0>;
							remote-endpoint = <0x73>;
							phandle = <0x91>;
						};

						endpoint@1 {
							reg = <0x1>;
							remote-endpoint = <0x74>;
							phandle = <0x93>;
						};
					};
				};
			};
		};

		phy@5509000 {
			compatible = "allwinner,sunxi-dsi-combo-phy1,sun60iw2";
			reg = <0x0 0x5509000 0x0 0x1ff>;
			clocks = <0x75>;
			clock-names = "phy_clk";
			#phy-cells = <0x0>;
			status = "disabled";
			phandle = <0x76>;
		};

		dsi1@5508000 {
			compatible = "allwinner,dsi1";
			reg = <0x0 0x5508000 0x0 0xfff>;
			interrupts = <0x0 0x3c 0x4>;
			clocks = <0x75>;
			clock-names = "dsi_clk";
			phys = <0x76>;
			phy-names = "combophy";
			status = "disabled";

			ports {
				#address-cells = <0x1>;
				#size-cells = <0x0>;

				port@0 {
					reg = <0x0>;
					#address-cells = <0x1>;
					#size-cells = <0x0>;

					endpoint@1 {
						reg = <0x0>;
						remote-endpoint = <0x77>;
						phandle = <0x66>;
					};

					endpoint@0 {
						reg = <0x1>;
						remote-endpoint = <0x78>;
						phandle = <0x60>;
					};
				};
			};
		};

		rgb0@0001000 {
			compatible = "allwinner,rgb0";
			status = "disabled";

			ports {
				#address-cells = <0x1>;
				#size-cells = <0x0>;

				port@0 {
					#address-cells = <0x1>;
					#size-cells = <0x0>;
					reg = <0x0>;

					endpoint@0 {
						reg = <0x0>;
						remote-endpoint = <0x4c>;
						phandle = <0x62>;
					};
				};
			};
		};

		lvds0@0001000 {
			compatible = "allwinner,lvds0";
			clocks = <0x79>;
			clock-names = "clk_lvds";
			phys = <0x6e 0x76>;
			phy-names = "combophy0", "combophy1";
			status = "disabled";

			ports {
				#address-cells = <0x1>;
				#size-cells = <0x0>;

				port@0 {
					#address-cells = <0x1>;
					#size-cells = <0x0>;
					reg = <0x0>;

					endpoint@0 {
						reg = <0x0>;
						remote-endpoint = <0x4b>;
						phandle = <0x61>;
					};
				};
			};
		};

		rgb1@0001000 {
			compatible = "allwinner,rgb1";
			reg = <0x0>;
			status = "disabled";

			ports {
				#address-cells = <0x1>;
				#size-cells = <0x0>;

				port@0 {
					#address-cells = <0x1>;
					#size-cells = <0x0>;
					reg = <0x0>;

					endpoint@0 {
						reg = <0x0>;
						remote-endpoint = <0x7a>;
						phandle = <0x6b>;
					};
				};
			};
		};

		lvds1@0001000 {
			compatible = "allwinner,lvds1";
			clocks = <0x7b>;
			clock-names = "clk_lvds";
			status = "disabled";

			ports {
				#address-cells = <0x1>;
				#size-cells = <0x0>;

				port@0 {
					#address-cells = <0x1>;
					#size-cells = <0x0>;
					reg = <0x0>;

					endpoint@0 {
						reg = <0x0>;
						remote-endpoint = <0x7c>;
						phandle = <0x6a>;
					};
				};
			};
		};

		tcon3@5730000 {
			compatible = "allwinner,tcon-tv";
			reg = <0x0 0x5730000 0x0 0x1000>;
			interrupts = <0x0 0x39 0x4>;
			clocks = <0x7d 0x7e>;
			clock-names = "clk_tcon", "rst_bus_tcon";
			top = <0x7f>;
			status = "okay";

			ports {
				#address-cells = <0x1>;
				#size-cells = <0x0>;

				port@0 {
					#address-cells = <0x1>;
					#size-cells = <0x0>;
					reg = <0x0>;

					endpoint@0 {
						reg = <0x0>;
						remote-endpoint = <0x80>;
						phandle = <0x53>;
					};

					endpoint@1 {
						reg = <0x1>;
						remote-endpoint = <0x4e>;
						phandle = <0x58>;
					};
				};

				port@1 {
					#address-cells = <0x1>;
					#size-cells = <0x0>;
					reg = <0x1>;

					endpoint@0 {
						reg = <0x0>;
						remote-endpoint = <0x81>;
						phandle = <0x4f>;
					};
				};
			};
		};

		tcon4@5731000 {
			compatible = "allwinner,tcon-tv";
			reg = <0x0 0x5731000 0x0 0x1000>;
			interrupts = <0x0 0x3a 0x4>;
			clocks = <0xe 0x82>;
			clock-names = "clk_tcon", "clk_bus_tcon";
			top = <0x7f>;
			status = "disabled";

			ports {
				#address-cells = <0x1>;
				#size-cells = <0x0>;

				port@0 {
					reg = <0x0>;
					#address-cells = <0x1>;
					#size-cells = <0x0>;

					endpoint@0 {
						reg = <0x0>;
						remote-endpoint = <0x48>;
						phandle = <0x54>;
					};

					endpoint@1 {
						reg = <0x1>;
						remote-endpoint = <0x83>;
						phandle = <0x59>;
					};
				};

				port@1 {
					#address-cells = <0x1>;
					#size-cells = <0x0>;
					reg = <0x1>;

					endpoint@0 {
						reg = <0x0>;
						remote-endpoint = <0x84>;
						phandle = <0x49>;
					};
				};
			};
		};

		drm_edp@5720000 {
			compatible = "allwinner,drm-dp";
			reg = <0x0 0x5740000 0x0 0x1000 0x0 0x5760000 0x0 0x20>;
			interrupts = <0x0 0x3e 0x4>;
			clocks = <0xe>;
			clock-names = "clk_edp";
			phys = <0x85 0x63 0x86 0x6>;
			phy-names = "aux-phy", "dp-phy";
			pclk_limit = <0x30d40>;
			status = "disabled";

			ports {
				#address-cells = <0x1>;
				#size-cells = <0x0>;

				port@0 {
					#address-cells = <0x1>;
					#size-cells = <0x0>;
					reg = <0x0>;

					endpoint@0 {
						reg = <0x0>;
						remote-endpoint = <0x49>;
						phandle = <0x84>;
					};
				};

				port@1 {
					#address-cells = <0x1>;
					#size-cells = <0x0>;
					reg = <0x1>;
				};
			};
		};

		hdmi@5520000 {
			compatible = "allwinner,sunxi-hdmi";
			reg = <0x0 0x5520000 0x0 0x100000>;
			interrupts = <0x0 0x3d 0x4>;
			clocks = <0x7d 0x87 0x88 0x89 0x8a>;
			clock-names = "clk_tcon_tv", "clk_hdmi", "clk_hdmi_24M", "rst_main", "rst_sub";
			assigned-clocks = <0x87>;
			assigned-clock-rates = <0x0 0x0>;
			status = "okay";
			uhdmi_fast_output = <0x0>;
			dcdc2-supply = <0x8b>;
			hdmi_power0 = "dcdc2";
			hdmi_power_cnt = <0x1>;
			uhdmi_resistor_select = <0x1>;
			snps_phy = <0x61a8 0x28488 0x7 0x280 0x8082 0x28488 0x53020 0x4 0x8240 0x80c3 0x53020 0x927c0 0x0 0x200 0x80f9>;

			ports {
				#address-cells = <0x1>;
				#size-cells = <0x0>;

				port@0 {
					#address-cells = <0x1>;
					#size-cells = <0x0>;
					reg = <0x0>;

					endpoint@0 {
						reg = <0x0>;
						remote-endpoint = <0x4f>;
						phandle = <0x81>;
					};
				};
			};
		};

		key_detect_en {
			key_type = "gpiokey";
			volume-down-gpios = <0x1d 0x1 0x0 0x0 0x1 0x3 0x1>;
			volume-up-gpios = <0x1d 0x1 0x1 0x0 0x1 0x3 0x1>;
			active-level = <0x0>;
		};
	};

	sunxi_dram_para_select {
		compatible = "allwinner,sunxi-dram-para-select";
		select_mode = <0x3>;
		gpadc_channel = <0x1>;
		status = "okay";
		pinctrl-0 = <0x8c>;
	};

	interrupt-controller@3020000 {
		compatible = "arm,cortex-a15-gic", "arm,cortex-a9-gic";
		#interrupt-cells = <0x3>;
		#address-cells = <0x0>;
		device_type = "gic";
		interrupt-controller;
		reg = <0x0 0x3021000 0x0 0x1000 0x0 0x3022000 0x0 0x2000 0x0 0x3024000 0x0 0x2000 0x0 0x3026000 0x0 0x2000>;
		interrupts = <0x1 0x9 0xf04>;
		interrupt-parent = <0x8d>;
		phandle = <0x8d>;
	};

	aliases@45100000 {
		pwmchip0 = "/soc@29000000/pwmchip0@2527000";
		pwmchip1 = "/soc@29000000/pwmchip1@2528000";
		pwmchip2 = "/soc@29000000/spwm0@7023000";
		pwm0 = "/soc@29000000/pwm0@2527010";
		pwm1 = "/soc@29000000/pwm1@2527011";
		pwm2 = "/soc@29000000/pwm2@2527012";
		pwm3 = "/soc@29000000/pwm3@2527013";
		pwm4 = "/soc@29000000/pwm4@2527014";
		pwm19 = "/soc@29000000/pwm19@2528019";
		twi1 = "/soc@29000000/twi@0x2511000";
		twi2 = "/soc@29000000/twi@0x2512000";
		twi6 = "/soc@29000000/s_twi@0x07083000";
		twi7 = "/soc@29000000/twi@2517000";
		pmu0 = "/soc@29000000/s_twi@0x07083000/pmu@34";
		ocp2131 = "/soc@29000000/twi@2517000/ocp2131@3e";
	};

	backlight0 {
		compatible = "pwm-backlight";
		status = "okay";
		brightness-levels = <0x0 0x1 0x2 0x3 0x4 0x5 0x6 0x7 0x8 0x9 0xa 0xb 0xc 0xd 0xe 0xf 0x10 0x11 0x12 0x13 0x14 0x15 0x16 0x17 0x18 0x19 0x1a 0x1b 0x1c 0x1d 0x1e 0x1f 0x20 0x21 0x22 0x23 0x24 0x25 0x26 0x27 0x28 0x29 0x2a 0x2b 0x2c 0x2d 0x2e 0x2f 0x30 0x31 0x32 0x33 0x34 0x35 0x36 0x37 0x38 0x39 0x3a 0x3b 0x3c 0x3d 0x3e 0x3f 0x40 0x41 0x42 0x43 0x44 0x45 0x46 0x47 0x48 0x49 0x4a 0x4b 0x4c 0x4d 0x4e 0x4f 0x50 0x51 0x52 0x53 0x54 0x55 0x56 0x57 0x58 0x59 0x5a 0x5b 0x5c 0x5d 0x5e 0x5f 0x60 0x61 0x62 0x63 0x64 0x65 0x66 0x67 0x68 0x69 0x6a 0x6b 0x6c 0x6d 0x6e 0x6f 0x70 0x71 0x72 0x73 0x74 0x75 0x76 0x77 0x78 0x79 0x7a 0x7b 0x7c 0x7d 0x7e 0x7f 0x80 0x81 0x82 0x83 0x84 0x85 0x86 0x87 0x88 0x89 0x8a 0x8b 0x8c 0x8d 0x8e 0x8f 0x90 0x91 0x92 0x93 0x94 0x95 0x96 0x97 0x98 0x99 0x9a 0x9b 0x9c 0x9d 0x9e 0x9f 0xa0 0xa1 0xa2 0xa3 0xa4 0xa5 0xa6 0xa7 0xa8 0xa9 0xaa 0xab 0xac 0xad 0xae 0xaf 0xb0 0xb1 0xb2 0xb3 0xb4 0xb5 0xb6 0xb7 0xb8 0xb9 0xba 0xbb 0xbc 0xbd 0xbe 0xbf 0xc0 0xc1 0xc2 0xc3 0xc4 0xc5 0xc6 0xc7 0xc8 0xc9 0xca 0xcb 0xcc 0xcd 0xce 0xcf 0xd0 0xd1 0xd2 0xd3 0xd4 0xd5 0xd6 0xd7 0xd8 0xd9 0xda 0xdb 0xdc 0xdd 0xde 0xdf 0xe0 0xe1 0xe2 0xe3 0xe4 0xe5 0xe6 0xe7 0xe8 0xe9 0xea 0xeb 0xec 0xed 0xee 0xef 0xf0 0xf1 0xf2 0xf3 0xf4 0xf5 0xf6 0xf7 0xf8 0xf9 0xfa 0xfb 0xfc 0xfd 0xfe 0xff>;
		default-brightness-level = <0x49>;
		pwms = <0x1e 0x3 0x61a8 0x0>;
		phandle = <0x8f>;
	};

	panel_0@0 {
		status = "okay";
		power-delay-ms = <0xa>;
		power0-supply = <0x8e>;
		power1-supply = <0x16>;
		enable0-gpios = <0x1d 0x7 0x13 0x1 0x0 0x3 0x1>;
		enable1-gpios = <0x1d 0x7 0x9 0x1 0x0 0x3 0x1>;
		enable2-gpios = <0x1d 0x7 0xa 0x1 0x0 0x3 0x1>;
		reset-on-sequence = <0x1 0xa 0x0 0xa 0x1 0xa 0x0 0xa 0x1 0x78>;
		reset-off-sequence = <0x0 0x78>;
		reset-gpios = <0x1d 0x3 0xf 0x1 0x0 0x3 0x1>;
		backlight = <0x8f>;
		width-mm = <0x8f>;
		height-mm = <0xee>;
		dsi,flags = <0x1>;
		dsi,lanes = <0x4>;
		dsi,format = <0x0>;
		panel-init-sequence = <0x390004b9 0x83102e15 0x2e9c3 0x150002d0 0x5150002 0xe9003900 0x5d1670c 0xff053900 0x12b110fa 0xafaf2d2d 0xa2445838 0x38383822 0x21150039 0x3d22d 0x2d390011 0xb200b047 0x80002c48 0x30111100 0x1520d7 0x39000c 0xb4886401 0x1886488 0x64019001 0x390009ba 0x7003a885 0xf200c00d 0x390004bf 0xfc858039 0xfc023 0x232211a2 0x17008000 0x80063 0x63150002 0xc7303900 0x9c80004 0x4000082 0x13013900 0x6cb0013 0x8024d15 0x2cc02 0x39002cd3 0x0 0x3c040000 0x4b40a4 0x4f2b2b04 0x4321025 0x253217 0xab07ab32 0x17b007b0 0x2138 0x1552138 0x1550f39 0x2dd518 0x18181818 0x183a3a18 0x1818182a 0x2b1a1a1b 0x1b242526 0x2728292a 0x2b000102 0x3040506 0x708090a 0xb202118 0x18181839 0x19d8aa 0xaaaaaaaa 0xa0aaaaaa 0xaaaaa0aa 0xaaeaaaaa 0xa0aaaaea 0xaaaaa039 0x2fe000 0x40c1218 0x253b4147 0x435d6369 0x79767d85 0x98974a53 0x5c630004 0xc121825 0x3b414743 0x5d636979 0x767d8598 0x974a535c 0x63390018 0xe7121302 0x255000e 0xe002627 0x76297601 0x1000000 0x170068 0x150002bd 0x1390005 0xb1019b01 0x3139000b 0xcbf43612 0x16c0286c 0x853f0439 0xcd301 0xf80000 0x1110000a 0x13900 0x19d8ffff 0xfffffff0 0xffffffff 0xfff05555 0x55555555 0x55555555 0x55553900 0x8e7022c 0x18d0dcd 0xe150002 0xbd023900 0x7b44e00 0x33113388 0x390004bf 0xf2000239 0x6cb00 0x3000199 0x39000dd8 0xffffffff 0xfff0ffff 0xfffffff0 0x39001de7 0xfd01fd01 0x2400 0x0 0x0 0x0 0x0 0x81010240 0x150002bd 0x3390019 0xd8aaabea 0xaaaaa0aa 0xabeaaaaa 0xa0aabfea 0xbffea0aa 0xbfeabffe 0xa0150002 0xbd001500 0x2e9cd15 0x2bb01 0x150002e9 0x390003 0xb8400015 0x2bd01 0x150002b8 0x15150002 0xbd003900 0x3e10001 0x390003be 0x1961500 0x2d93f39 0x4b900 0x1596 0x2110015 0x32022900>;
		panel-exit-sequence = <0x5000128 0x5780110>;

		display-timings {
			native-mode = <0x90>;

			timing1 {
				clock-frequency = <0x92d1730>;
				hback-porch = <0x16>;
				hactive = <0x4b0>;
				hfront-porch = <0x1c>;
				hsync-len = <0x8>;
				vback-porch = <0x26>;
				vactive = <0x780>;
				vfront-porch = <0x48>;
				vsync-len = <0x8>;
				phandle = <0x90>;
			};
		};

		port {

			endpoint@0 {
				reg = <0x0>;
				remote-endpoint = <0x91>;
				phandle = <0x73>;
			};
		};
	};

	panel_1@0 {
		status = "disabled";
		power-delay-ms = <0x32>;
		power0-supply = <0x16>;
		enable0-gpios = <0x1d 0x7 0x13 0x1 0x0 0x3 0x1>;
		enable1-gpios = <0x1d 0x7 0x9 0x1 0x0 0x3 0x1>;
		enable2-gpios = <0x1d 0x7 0xa 0x1 0x0 0x3 0x1>;
		reset-num = <0x2>;
		reset-delay-ms = <0xa>;
		reset-gpios = <0x1d 0x3 0xf 0x1 0x0 0x3 0x1>;
		backlight = <0x8f>;
		width-mm = <0x8f>;
		height-mm = <0xee>;
		dsi,flags = <0x1>;
		dsi,lanes = <0x4>;
		dsi,format = <0x0>;
		panel-init-sequence = [15 96 02 11 00 15 32 02 29 00];
		panel-exit-sequence = <0x5000128 0x5780110>;

		display-timings {
			native-mode = <0x92>;

			timing0 {
				clock-frequency = <0x95b8660>;
				hback-porch = <0x14>;
				hactive = <0x4b0>;
				hfront-porch = <0x1c>;
				hsync-len = <0x8>;
				vback-porch = <0x1e>;
				vactive = <0x780>;
				vfront-porch = <0x84>;
				vsync-len = <0x8>;
				phandle = <0x92>;
			};
		};

		port {

			endpoint@0 {
				reg = <0x0>;
				remote-endpoint = <0x93>;
				phandle = <0x74>;
			};
		};
	};
};
